# ODS5010 register map
Vendor: OCS; Series: ODS5010; File version: 1.0
CPU: CM0plus r0p0, little endian, MPU, FPU, 4 interrupt priority bits
Registers are 32-bit, read-write, reset 0x0 unless marked. A register's access mark holds for its fields unless they carry their own. Offsets are from the block's base; [hi:lo] are bit positions.

## I2C0 — Inter-Integrated Circuit (I2C0) Peripheral
Base 0x40005400; register names take the prefix I2C_0
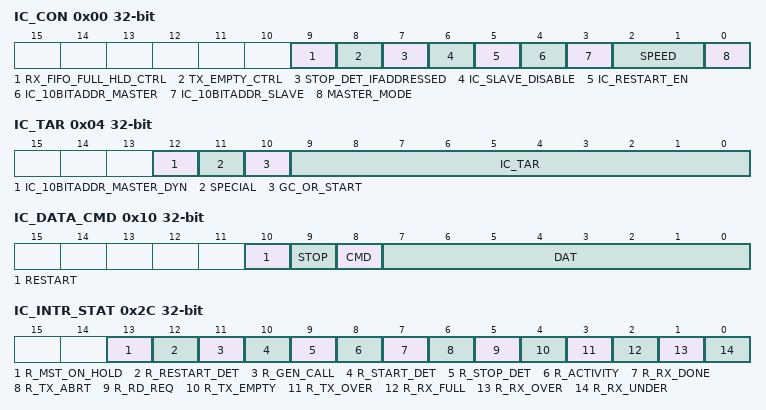
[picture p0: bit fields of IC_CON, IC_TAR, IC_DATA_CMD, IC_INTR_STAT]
0x00 IC_CON — I2C Control Register
  [9] RX_FIFO_FULL_HLD_CTRL — RX FIFO Full Hold Control
  [8] TX_EMPTY_CTRL — TX Empty Control
  [7] STOP_DET_IFADDRESSED — Stop Detection if Addressed
  [6] IC_SLAVE_DISABLE — Slave Disable
  [5] IC_RESTART_EN — Restart Enable
  [4] IC_10BITADDR_MASTER — 10-bit Addressing in Master Mode
  [3] IC_10BITADDR_SLAVE — 10-bit Addressing in Slave Mode
  [2:1] SPEED
  [0] MASTER_MODE
0x04 IC_TAR — I2C Target Address Register
  [12] IC_10BITADDR_MASTER_DYN — 10-bit Addressing Master (Dynamic)
  [11] SPECIAL — Special Command
  [10] GC_OR_START — General Call or Start Byte
  [9:0] IC_TAR — Target Address
0x08 IC_SAR — I2C Slave Address Register
  [9:0] IC_SAR — Slave Address
0x0C IC_HS_MADDR — I2C High-Speed Master Mode Code Address Register
  [2:0] IC_HS_MAR — High-Speed Master Code
0x10 IC_DATA_CMD — I2C Data Buffer and Command Register
  [10] RESTART — Restart Condition
  [9] STOP — Stop Condition
  [8] CMD — Command (Read/Write)
  [7:0] DAT — Data
0x14 IC_SS_SCL_HCNT — Standard Speed SCL High Count Register
0x18 IC_SS_SCL_LCNT — Standard Speed SCL Low Count Register
0x1C IC_FS_SCL_HCNT — Fast Speed SCL High Count Register
0x20 IC_FS_SCL_LCNT — Fast Speed SCL Low Count Register
0x24 IC_HS_SCL_HCNT — High-Speed SCL High Count Register
0x28 IC_HS_SCL_LCNT — High-Speed SCL Low Count Register
0x2C IC_INTR_STAT — Interrupt Status Register
  [13] R_MST_ON_HOLD — Master on Hold
  [12] R_RESTART_DET — Restart Detection
  [11] R_GEN_CALL — General Call
  [10] R_START_DET — Start Detection
  [9] R_STOP_DET — Stop Detection
  [8] R_ACTIVITY — Activity
  [7] R_RX_DONE — RX Done
  [6] R_TX_ABRT — TX Abort
  [5] R_RD_REQ — Read Request
  [4] R_TX_EMPTY — TX Empty
  [3] R_TX_OVER — TX Overflow
  [2] R_RX_FULL — RX Full
  [1] R_RX_OVER — RX Overflow
  [0] R_RX_UNDER — RX Underflow
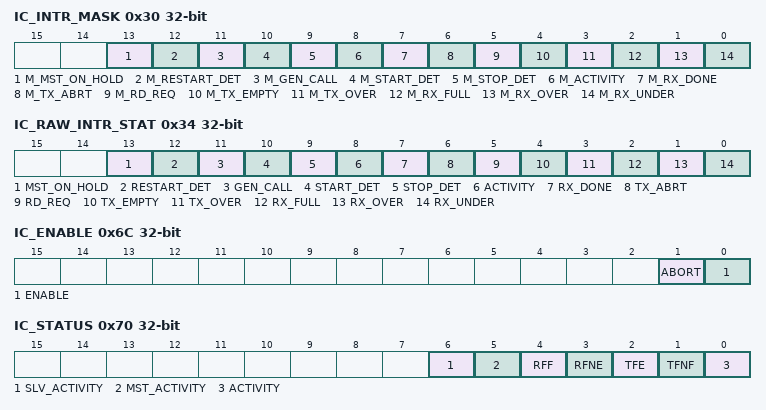
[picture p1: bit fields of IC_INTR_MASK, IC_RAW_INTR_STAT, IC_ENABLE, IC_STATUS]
0x30 IC_INTR_MASK — Interrupt Mask Register
  [13] M_MST_ON_HOLD — Master on Hold Mask
  [12] M_RESTART_DET — Restart Detection Mask
  [11] M_GEN_CALL — General Call Mask
  [10] M_START_DET — Start Detection Mask
  [9] M_STOP_DET — Stop Detection Mask
  [8] M_ACTIVITY — Activity Mask
  [7] M_RX_DONE — RX Done Mask
  [6] M_TX_ABRT — TX Abort Mask
  [5] M_RD_REQ — Read Request Mask
  [4] M_TX_EMPTY — TX Empty Mask
  [3] M_TX_OVER — TX Overflow Mask
  [2] M_RX_FULL — RX Full Mask
  [1] M_RX_OVER — RX Overflow Mask
  [0] M_RX_UNDER — RX Underflow Mask
0x34 IC_RAW_INTR_STAT — Raw Interrupt Status Register
  [13] MST_ON_HOLD — Master on Hold Raw
  [12] RESTART_DET — Restart Detection Raw
  [11] GEN_CALL — General Call Raw
  [10] START_DET — Start Detection Raw
  [9] STOP_DET — Stop Detection Raw
  [8] ACTIVITY — Activity Raw
  [7] RX_DONE — RX Done Raw
  [6] TX_ABRT — TX Abort Raw
  [5] RD_REQ — Read Request Raw
  [4] TX_EMPTY — TX Empty Raw
  [3] TX_OVER — TX Overflow Raw
  [2] RX_FULL — RX Full Raw
  [1] RX_OVER — RX Overflow Raw
  [0] RX_UNDER — RX Underflow Raw
0x38 IC_RX_TL — Receive FIFO Threshold Level Register
  [7:0] RX_TL — RX Threshold Level
0x3C IC_TX_TL — Transmit FIFO Threshold Level Register
  [7:0] TX_TL — TX Threshold Level
0x40 IC_CLR_INTR — Clear Combined and Individual Interrupts Register
  [0] CLR_INTR — Clear Interrupt
0x44 IC_CLR_RX_UNDER — Clear RX_UNDER Interrupt Register
  [0] CLR_RX_UNDER — Clear RX Underflow
0x48 IC_CLR_RX_OVER — Clear RX_OVER Interrupt Register
  [0] CLR_RX_OVER — Clear RX Overflow
0x4C IC_CLR_TX_OVER — Clear TX_OVER Interrupt Register
  [0] CLR_TX_OVER — Clear TX Overflow
0x50 IC_CLR_RD_REQ — Clear RD_REQ Interrupt Register
  [0] CLR_RD_REQ — Clear Read Request
0x54 IC_CLR_TX_ABRT — Clear TX_ABRT Interrupt Register
  [0] CLR_TX_ABRT — Clear TX Abort
0x58 IC_CLR_RX_DONE — Clear RX_DONE Interrupt Register
  [0] CLR_RX_DONE — Clear RX Done
0x5C IC_CLR_ACTIVITY — Clear ACTIVITY Interrupt Register
  [0] CLR_ACTIVITY — Clear Activity
0x60 IC_CLR_STOP_DET — Clear STOP_DET Interrupt Register
  [0] CLR_STOP_DET — Clear Stop Detection
0x64 IC_CLR_START_DET — Clear START_DET Interrupt Register
  [0] CLR_START_DET — Clear Start Detection
0x68 IC_CLR_GEN_CALL — Clear GEN_CALL Interrupt Register
  [0] CLR_GEN_CALL — Clear General Call
0x6C IC_ENABLE — I2C Enable Register
  [1] ABORT, [0] ENABLE
0x70 IC_STATUS — I2C Status Register
  [6] SLV_ACTIVITY — Slave Activity
  [5] MST_ACTIVITY — Master Activity
  [4] RFF — RX FIFO Full
  [3] RFNE — RX FIFO Not Empty
  [2] TFE — TX FIFO Empty
  [1] TFNF — TX FIFO Not Full
  [0] ACTIVITY — Activity Status
0x74 IC_TXFLR — Transmit FIFO Level Register
  [7:0] TXFLR — TX FIFO Level
0x78 IC_RXFLR — Receive FIFO Level Register
  [7:0] RXFLR — RX FIFO Level
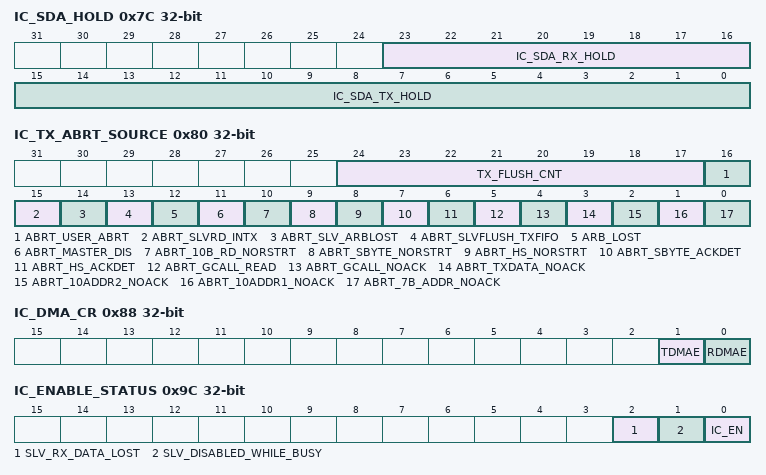
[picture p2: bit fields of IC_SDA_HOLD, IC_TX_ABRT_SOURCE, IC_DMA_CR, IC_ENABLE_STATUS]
0x7C IC_SDA_HOLD — SDA Hold Time Length Register
  [23:16] IC_SDA_RX_HOLD — SDA RX Hold Time
  [15:0] IC_SDA_TX_HOLD — SDA TX Hold Time
0x80 IC_TX_ABRT_SOURCE — Transmit Abort Source Register
  [24:17] TX_FLUSH_CNT — TX Flush Count
  [16] ABRT_USER_ABRT — User Abort
  [15] ABRT_SLVRD_INTX — Slave Read in TX
  [14] ABRT_SLV_ARBLOST — Slave Arbitration Lost
  [13] ABRT_SLVFLUSH_TXFIFO — Slave Flush TX FIFO
  [12] ARB_LOST — Arbitration Lost
  [11] ABRT_MASTER_DIS — Master Disabled
  [10] ABRT_10B_RD_NORSTRT — 10-bit Read No Restart
  [9] ABRT_SBYTE_NORSTRT — Start Byte No Restart
  [8] ABRT_HS_NORSTRT — HS No Restart
  [7] ABRT_SBYTE_ACKDET — Start Byte ACK Detect
  [6] ABRT_HS_ACKDET — HS ACK Detect
  [5] ABRT_GCALL_READ — General Call Read
  [4] ABRT_GCALL_NOACK — General Call No ACK
  [3] ABRT_TXDATA_NOACK — TX Data No ACK
  [2] ABRT_10ADDR2_NOACK — 10-bit Address2 No ACK
  [1] ABRT_10ADDR1_NOACK — 10-bit Address1 No ACK
  [0] ABRT_7B_ADDR_NOACK — 7-bit Address No ACK
0x84 IC_SLV_DATA_NACK_ONLY — Generate Slave Data NACK Register
  [0] NACK — Generate NACK
0x88 IC_DMA_CR — DMA Control Register
  [1] TDMAE — TX DMA Enable
  [0] RDMAE — RX DMA Enable
0x8C IC_DMA_TDLR — DMA Transmit Data Level Register
  [7:0] DMATDL — DMA TX Data Level
0x90 IC_DMA_RDLR — DMA Receive Data Level Register
  [7:0] DMARDL — DMA RX Data Level
0x94 IC_SDA_SETUP — SDA Setup Register
  [7:0] SDA_SETUP — SDA Setup Time
0x98 IC_ACK_GENERAL_CALL — ACK General Call Register
  [0] ACK_GEN_CALL — ACK General Call
0x9C IC_ENABLE_STATUS — Enable Status Register
  [2] SLV_RX_DATA_LOST — Slave RX Data Lost
  [1] SLV_DISABLED_WHILE_BUSY — Slave Disabled While Busy
  [0] IC_EN — I2C Enable Status
0xA0 IC_FS_SPKLEN — FS Spike Suppression Limit Register
  [7:0] IC_FS_SPKLEN — FS Spike Length
0xA4 IC_HS_SPKLEN — HS Spike Suppression Limit Register
  [7:0] IC_HS_SPKLEN — HS Spike Length
0xA8 IC_CLR_RESTART_DET — Clear RESTART_DET Interrupt Register
  [0] CLR_RESTART_DET — Clear Restart Detection
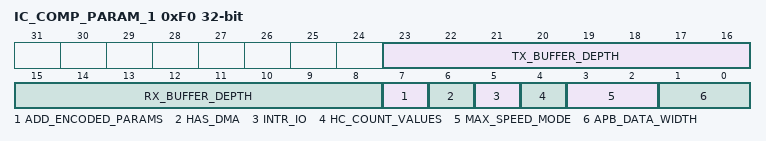
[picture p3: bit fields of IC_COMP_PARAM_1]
0xF0 IC_COMP_PARAM_1 — Component Parameter Register 1
  [23:16] TX_BUFFER_DEPTH
  [15:8] RX_BUFFER_DEPTH
  [7] ADD_ENCODED_PARAMS — Add Encoded Parameters
  [6] HAS_DMA
  [5] INTR_IO — Interrupt IO
  [4] HC_COUNT_VALUES — Hard-coded Count Values
  [3:2] MAX_SPEED_MODE
  [1:0] APB_DATA_WIDTH
0xF4 IC_COMP_VERSION — Component Version Register
  [31:0] VERSION — Component Version
0xFC IC_COMP_TYPE — Component Type Register
  [31:0] COMP_TYPE — Component Type

## I2C1 — Inter-Integrated Circuit (I2C1) Peripheral
Base 0x40005800; register names take the prefix I2C_1
Registers as I2C0.
